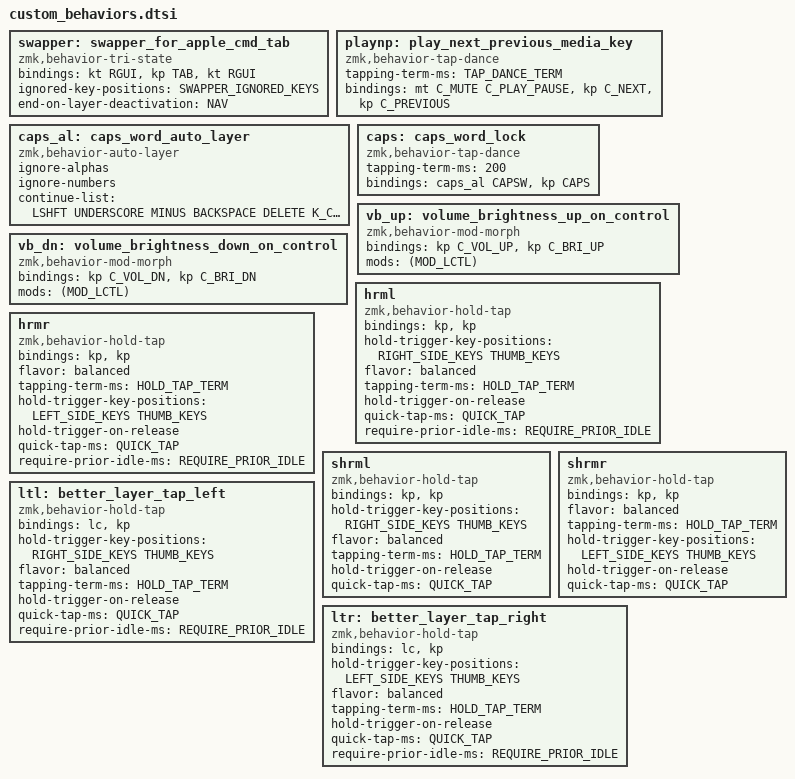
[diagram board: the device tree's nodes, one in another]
// Key references for custom behaviors using x_keypos.dtsi naming scheme

    // Key groups for home row mods and layer-taps
    #define LEFT_SIDE_KEYS LT0 LT1 LT2 LT3 LT4 LM0 LM1 LM2 LM3 LM4 LB0 LB1 LB2 LB3 LB4
    #define RIGHT_SIDE_KEYS RT0 RT1 RT2 RT3 RT4 RM0 RM1 RM2 RM3 RM4 RB0 RB1 RB2 RB3 RB4
    #define THUMB_KEYS LIT LHT RHT RIT

    // Keys ignored by the swapper for CMD+TAB behavior
    #define SWAPPER_IGNORED_KEYS LM2 RT2 RM1 RM2 RM3 RT4 RM4 RB4 // Shift, Arrows, BSPC, ENTER and DEL for alt-tab movement and window/app controls
    // LIT (the &lc NAV thumb) used to be in this list, which is what kept CMD held after leaving NAV:
    // the tri-state ends on any *non-ignored* position event, press or release, so the release of the
    // layer thumb is exactly the event that should tear it down. See &swapper below.

// Swapper for Apple's CMD+TAB behavior

    swapper: swapper_for_apple_cmd_tab {
        compatible = "zmk,behavior-tri-state"; // requires tri-state module (https://github.com/urob/zmk-tri-state)
        #binding-cells = <0>;
        bindings = <&kt RGUI>, <&kp TAB>, <&kt RGUI>;

        ignored-key-positions = <SWAPPER_IGNORED_KEYS>;
        end-on-layer-deactivation = <NAV>; // safety net: the module only ends on layer *activation* by default,
                                           // so a NAV drop with no accompanying key event would otherwise hold RGUI forever
                                           // (timeout-ms defaults to -1, i.e. no timeout at all)
    };

// Media controls

    playnp: play_next_previous_media_key { 
        compatible = "zmk,behavior-tap-dance";
        #binding-cells = <0>;
        tapping-term-ms = <TAP_DANCE_TERM>;
        bindings =
            <&mt C_MUTE C_PLAY_PAUSE>,
            <&kp C_NEXT>,
            <&kp C_PREVIOUS>;
    };

// Caps word rebuilt on top of urob's auto-layer
//
// ZMK's stock &caps_word hardcodes is_mod() in its deactivation check, so *no* modifier can ever
// cancel it, and it blindly OR's LSHFT into every alpha - which is how CMD+C became CMD+SHIFT+C.
// &auto_layer makes ignore-modifiers opt-in, so leaving it out means every modifier cancels CAPSW
// except the ones explicitly whitelisted below. The shifting itself comes from the CAPSW layer.

    caps_al: caps_word_auto_layer {
        compatible = "zmk,behavior-auto-layer"; // requires auto-layer module (https://github.com/urob/zmk-auto-layer)
        #binding-cells = <1>;
        ignore-alphas;      // letters are the whole point of the layer
        ignore-numbers;     // matches stock &caps_word, which never broke on digits either
        continue-list = <
            LSHFT                                       // only the home row shift survives; RSHFT is left out on purpose so the LHT thumb doubles as a CAPSW cancel
            UNDERSCORE MINUS BACKSPACE DELETE K_CANCEL  // K_CANCEL is for the &lc macro
            SQT CARET TILDE GRAVE SLASH                 // PT-BR diacriticals: these carry an *implicit* shift, no modifier keycode is emitted
            >;                                          // LALT/RALT/LGUI/RGUI/LCTRL/RCTRL are deliberately absent, so alt/option and command cancel CAPSW
    };

    caps: caps_word_lock { // currently unbound, kept as a one-key alternative to the LM2+RM2 combo
            compatible = "zmk,behavior-tap-dance";
            #binding-cells = <0>;
            tapping-term-ms = <200>;
            bindings = <&caps_al CAPSW>, <&kp CAPS>;
    };
    
    vb_up: volume_brightness_up_on_control {
        compatible = "zmk,behavior-mod-morph";
        #binding-cells = <0>;
        bindings = <&kp C_VOL_UP>, <&kp C_BRI_UP>;

        mods = <(MOD_LCTL)>;
    };

    vb_dn: volume_brightness_down_on_control {
        compatible = "zmk,behavior-mod-morph";
        #binding-cells = <0>;
        bindings = <&kp C_VOL_DN>, <&kp C_BRI_DN>;

        mods = <(MOD_LCTL)>;
    };

// Customized hold-tap definitions

    hrml: hrml { // urob's home row mods left
        compatible = "zmk,behavior-hold-tap";
        bindings = <&kp>, <&kp>;
        #binding-cells = <2>;
        // here's the magic
        hold-trigger-key-positions = <RIGHT_SIDE_KEYS THUMB_KEYS>;
        flavor = "balanced";
        tapping-term-ms = <HOLD_TAP_TERM>;
        hold-trigger-on-release;
        quick-tap-ms = <QUICK_TAP>;
        require-prior-idle-ms = <REQUIRE_PRIOR_IDLE>;
    };

    hrmr: hrmr { // urob's home row mods right
        compatible = "zmk,behavior-hold-tap";
        bindings = <&kp>, <&kp>;
        #binding-cells = <2>;
        // here's the magic
        flavor = "balanced";
        tapping-term-ms = <HOLD_TAP_TERM>;
        hold-trigger-key-positions = <LEFT_SIDE_KEYS THUMB_KEYS>;
        hold-trigger-on-release;
        quick-tap-ms = <QUICK_TAP>;
        require-prior-idle-ms = <REQUIRE_PRIOR_IDLE>;
    };


// Customized hold-tap definitions for shifts, without require-prior-idle to make them more responsive

    shrml: shrml { // urob's home row mods left
        compatible = "zmk,behavior-hold-tap";
        bindings = <&kp>, <&kp>;

        #binding-cells = <2>;
        hold-trigger-key-positions = <RIGHT_SIDE_KEYS THUMB_KEYS>;
        flavor = "balanced";
        tapping-term-ms = <HOLD_TAP_TERM>;
        hold-trigger-on-release;
        quick-tap-ms = <QUICK_TAP>;
    };

    shrmr: shrmr { // urob's home row mods right
        compatible = "zmk,behavior-hold-tap";
        bindings = <&kp>, <&kp>;

        #binding-cells = <2>;
        flavor = "balanced";
        tapping-term-ms = <HOLD_TAP_TERM>;
        hold-trigger-key-positions = <LEFT_SIDE_KEYS THUMB_KEYS>;
        hold-trigger-on-release;
        quick-tap-ms = <QUICK_TAP>;
    };

// Customized balanced layer-tap

    ltl: better_layer_tap_left { // urob's logic but for a layer-tap on left hand
        compatible = "zmk,behavior-hold-tap";
        bindings = <&lc>, <&kp>;

        #binding-cells = <2>;
        hold-trigger-key-positions = <RIGHT_SIDE_KEYS THUMB_KEYS>;
        flavor = "balanced";
        tapping-term-ms = <HOLD_TAP_TERM>;
        hold-trigger-on-release;
        quick-tap-ms = <QUICK_TAP>;
        require-prior-idle-ms = <REQUIRE_PRIOR_IDLE>;
    };

    ltr: better_layer_tap_right { // urob's logic but for a layer-tap on right hand
        compatible = "zmk,behavior-hold-tap";
        bindings = <&lc>, <&kp>;

        #binding-cells = <2>;
        hold-trigger-key-positions = <LEFT_SIDE_KEYS THUMB_KEYS>;
        flavor = "balanced";
        tapping-term-ms = <HOLD_TAP_TERM>;
        hold-trigger-on-release;
        quick-tap-ms = <QUICK_TAP>;
        require-prior-idle-ms = <REQUIRE_PRIOR_IDLE>;
    };

